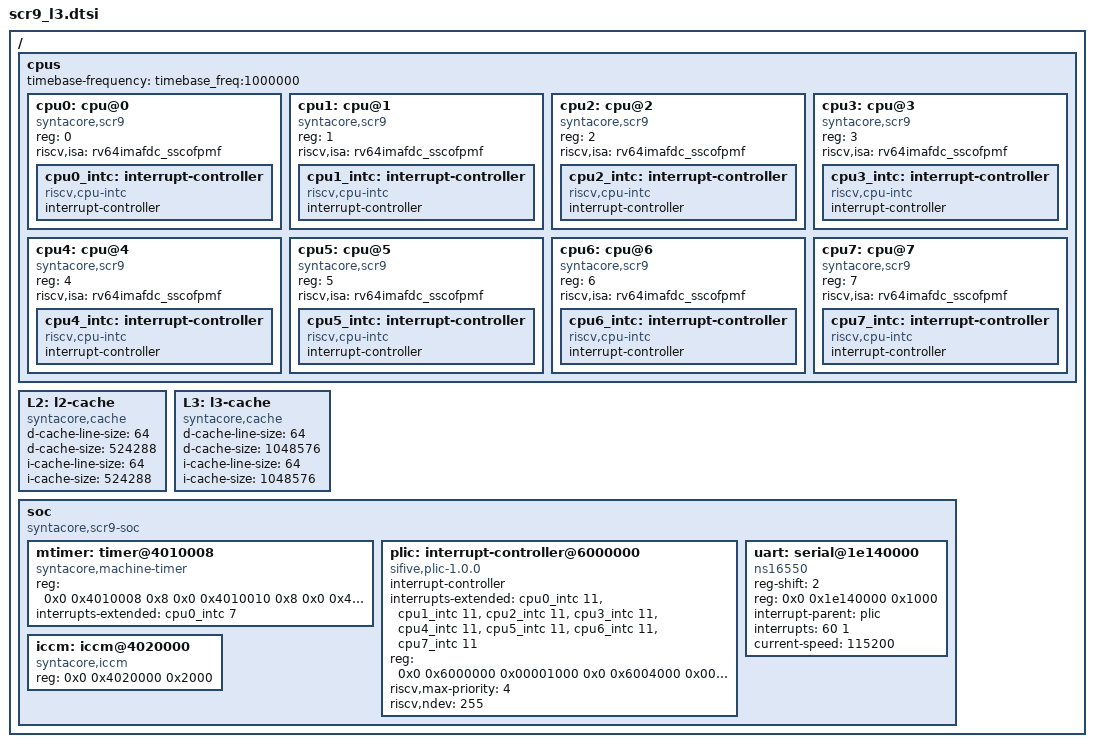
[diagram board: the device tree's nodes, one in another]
/*
 * Copyright (C) 2026, Syntacore Ltd.
 *
 * Licensed under the Apache License, Version 2.0 (the "License");
 * you may not use this file except in compliance with the License.
 * You may obtain a copy of the License at
 *     http://www.apache.org/licenses/LICENSE-2.0
 * Unless required by applicable law or agreed to in writing, software
 * distributed under the License is distributed on an "AS IS" BASIS,
 * WITHOUT WARRANTIES OR CONDITIONS OF ANY KIND, either express or implied.
 * See the License for the specific language governing permissions and
 * limitations under the License.
 */

#include <mem.h>

/dts-v1/;

/ {
	#address-cells = <1>;
	#size-cells = <1>;

	cpus {
		#address-cells = <1>;
		#size-cells = <0>;
		timebase-frequency = <timebase_freq:1000000>;

		cpu0: cpu@0 {
			compatible ="syntacore,scr9", "riscv";
			reg = <0>;
			riscv,isa = "rv64imafdc_sscofpmf";
			
			cpu0_intc: interrupt-controller {
				compatible = "riscv,cpu-intc";
				#address-cells = <0>;
				#interrupt-cells = <1>;
				interrupt-controller;
			};
		};
		
		cpu1: cpu@1 {
			compatible ="syntacore,scr9", "riscv";
			reg = <1>;
			riscv,isa = "rv64imafdc_sscofpmf";
			
			cpu1_intc: interrupt-controller {
				compatible = "riscv,cpu-intc";
				#address-cells = <0>;
				#interrupt-cells = <1>;
				interrupt-controller;
			};
		};
		
		cpu2: cpu@2 {
			compatible ="syntacore,scr9", "riscv";
			reg = <2>;
			riscv,isa = "rv64imafdc_sscofpmf";
			
			cpu2_intc: interrupt-controller {
				compatible = "riscv,cpu-intc";
				#address-cells = <0>;
				#interrupt-cells = <1>;
				interrupt-controller;
			};
		};
		
		cpu3: cpu@3 {
			compatible ="syntacore,scr9", "riscv";
			reg = <3>;
			riscv,isa = "rv64imafdc_sscofpmf";
			
			cpu3_intc: interrupt-controller {
				compatible = "riscv,cpu-intc";
				#address-cells = <0>;
				#interrupt-cells = <1>;
				interrupt-controller;
			};
		};
		
		cpu4: cpu@4 {
			compatible ="syntacore,scr9", "riscv";
			reg = <4>;
			riscv,isa = "rv64imafdc_sscofpmf";
			
			cpu4_intc: interrupt-controller {
				compatible = "riscv,cpu-intc";
				#address-cells = <0>;
				#interrupt-cells = <1>;
				interrupt-controller;
			};
		};
		
		cpu5: cpu@5 {
			compatible ="syntacore,scr9", "riscv";
			reg = <5>;
			riscv,isa = "rv64imafdc_sscofpmf";
			
			cpu5_intc: interrupt-controller {
				compatible = "riscv,cpu-intc";
				#address-cells = <0>;
				#interrupt-cells = <1>;
				interrupt-controller;
			};
		};
		
		cpu6: cpu@6 {
			compatible ="syntacore,scr9", "riscv";
			reg = <6>;
			riscv,isa = "rv64imafdc_sscofpmf";
			
			cpu6_intc: interrupt-controller {
				compatible = "riscv,cpu-intc";
				#address-cells = <0>;
				#interrupt-cells = <1>;
				interrupt-controller;
			};
		};
		
		cpu7: cpu@7 {
			compatible ="syntacore,scr9", "riscv";
			reg = <7>;
			riscv,isa = "rv64imafdc_sscofpmf";
			
			cpu7_intc: interrupt-controller {
				compatible = "riscv,cpu-intc";
				#address-cells = <0>;
				#interrupt-cells = <1>;
				interrupt-controller;
			};
		};
	};

	L2: l2-cache {
		compatible = "syntacore,cache";
		d-cache-line-size = <64>;
		d-cache-size = <524288>;
		i-cache-line-size = <64>;
		i-cache-size = <524288>;
	};
	
	L3: l3-cache {
		compatible = "syntacore,cache";
		d-cache-line-size = <64>;
		d-cache-size = <1048576>;
		i-cache-line-size = <64>;
		i-cache-size = <1048576>;
	};

	soc {
		#address-cells = <2>;
		#size-cells = <1>;
		compatible = "syntacore,scr9-soc";

		mtimer: timer@4010008 {
			compatible = "syntacore,machine-timer";
			reg = <0x0 0x4010008 0x8
				0x0 0x4010010 0x8
				0x0 0x4010004 0x4
				0x0 0x4010000 0x2000>;
			reg-names = "mtime", "mtimecmp", "mtimediv", "base";
			interrupts-extended = <&cpu0_intc 7>;
		};

		plic: interrupt-controller@6000000 {
			#address-cells = <2>;
			#interrupt-cells = <2>;
			compatible = "sifive,plic-1.0.0", "riscv,plic0";
			interrupt-controller;
			interrupts-extended = <&cpu0_intc 11
				&cpu1_intc 11
				&cpu2_intc 11
				&cpu3_intc 11
				&cpu4_intc 11
				&cpu5_intc 11
				&cpu6_intc 11
				&cpu7_intc 11>;

			reg = <0x0 0x6000000 0x00001000
			0x0 0x6004000  0x00004000
			0x0 0x6200000  0x00040000 >;			
			reg-names = "prio", "irq_en", "reg";

			riscv,max-priority = <4>;
			riscv,ndev = <255>;
		};

		uart: serial@1e140000 {
			compatible = "ns16550";
			reg-shift = < 2 >;
			reg = <0x0 0x1e140000 0x1000>;
			interrupt-parent = <&plic>;
			interrupts = <60 1>; // IRQ PRIO
			current-speed = <115200>;
			status = "okay";
		};
		
		iccm: iccm@4020000 {
			compatible = "syntacore,iccm";
			reg = <0x0 0x4020000 0x2000>;
		};
	};
};
